# CY8C3246PVI_147 register map
File version: 0.1
CY8C32
Registers are 8-bit, read-write, no defined reset value unless marked. A register's access mark holds for its fields unless they carry their own. Offsets are from the block's base; lines under a group give offsets from that group; [hi:lo] are bit positions; {n}, {i} and the like mark numbered series; 'fields as' and 'values as' point back to an identical list; <NAME> marks a mode.

## Memory map
0x000043A3 PACER_TIMER size 0xB64
0x000043AA ADC size 0x17E0
0x00006404 MY_TIMER size 0x92
0x0000640B COUNTER_ENC size 0x91
0x0000642D UART_RS485 size 0x43 — UART
0x0000646E FF_STATUS size 0x31
0x00006474 FTDI_ENABLE_REG size 0x1
0x0000647C MOTOR_ON_OFF size 0x1
0x0000647D RS485_CTS size 0x1
0x0000647F RESET_FF size 0x1
0x00006527 PWM_MOTORS size 0x71
0x00006574 MOTOR_DIR size 0x1
0x0000657B LED_REG size 0x1

## LED_REG
Base 0x0000657B
0x00 LED_REG_CONTROL_REG

## RS485_CTS
Base 0x0000647D
Registers as LED_REG (with LED_REG read as RS485_CTS).

## RESET_FF
Base 0x0000647F
Registers as LED_REG (with LED_REG read as RESET_FF).

## MOTOR_ON_OFF
Base 0x0000647C
Registers as LED_REG (with LED_REG read as MOTOR_ON_OFF).

## FTDI_ENABLE_REG
Base 0x00006474
Registers as LED_REG (with LED_REG read as FTDI_ENABLE_REG).

## MOTOR_DIR
Base 0x00006574
Registers as LED_REG (with LED_REG read as MOTOR_DIR).

## FF_STATUS
Base 0x0000646E
0x00 FF_STATUS_STATUS_REG
0x20 FF_STATUS_MASK_REG
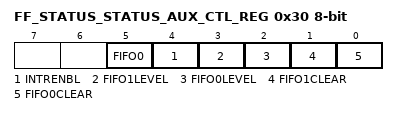
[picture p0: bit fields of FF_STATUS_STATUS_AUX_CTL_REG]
0x30 FF_STATUS_STATUS_AUX_CTL_REG
  [5] FIFO0 — FIFO0 clear
    1=ENABLED (Enable counter); 0=DISABLED (Disable counter)
  [4] INTRENBL — Enables or disables the Interrupt
    1=ENABLED (Interrupt enabled); 0=DISABLED (Interrupt disabled)
  [3] FIFO1LEVEL — FIFO level
    1=ENABLED (FIFO LVL: input mode: FIFO at least 1/2 empty; output mode: FIFO at least 1/2 full); 0=DISABLED (FIFO LVL: input mode: FIFO not full; output mode: FIFO not empty)
  [2] FIFO0LEVEL — FIFO level
    values as FIFO1LEVEL
  [1] FIFO1CLEAR — FIFO clear
    1=ENABLED (Clear FIFO state); 0=DISABLED (Normal FIFO operation)
  [0] FIFO0CLEAR — FIFO clear
    values as FIFO1CLEAR

## MY_TIMER
Base 0x00006404
0x00 MY_TIMER_COUNTER 16-bit — UDB.A0 - Current Down Counter Value
0x20 MY_TIMER_PERIOD 16-bit — UDB.D0 - Assigned Period
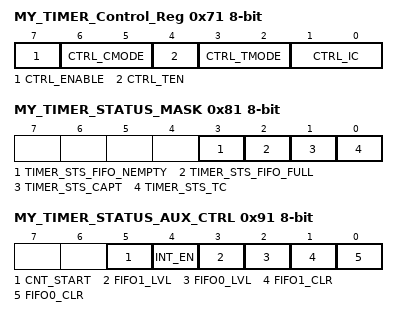
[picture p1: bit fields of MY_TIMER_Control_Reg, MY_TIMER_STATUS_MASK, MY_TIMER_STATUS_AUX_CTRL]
0x71 MY_TIMER_Control_Reg — UDB Control Register - Assigned Control Register Value
  [7] CTRL_ENABLE — Enable the Timer
  [6:5] CTRL_CMODE — Capture Mode
  [4] CTRL_TEN — Trigger Enable Bit
  [3:2] CTRL_TMODE — Trigger Mode
  [1:0] CTRL_IC — Interrupt Count
0x81 MY_TIMER_STATUS_MASK — UDB Status bits Interrupt Mask Enable Register
  [3] TIMER_STS_FIFO_NEMPTY ro — FIFO Empty status
  [2] TIMER_STS_FIFO_FULL ro — FIFO Full Status
  [1] TIMER_STS_CAPT ro — Enables the Interrupt on Capture
  [0] TIMER_STS_TC ro — Enables the Interrupt on TC
0x91 MY_TIMER_STATUS_AUX_CTRL — UDB Auxilliary Control Register
  [5] CNT_START — FIFO0 clear
    0=E_CNT_START0 (Disable counter); 1=E_CNT_START1 (Enable counter)
  [4] INT_EN
    0=E_INT_EN0 (Interrupt disabled); 1=E_INT_EN1 (Interrupt enabled)
  [3] FIFO1_LVL — FIFO level
    0=E_FIFO_LVL_0 (FIFO LVL: input mode: FIFO not full; output mode: FIFO not empty); 1=E_FIFO_LVL_1 (FIFO LVL: input mode: FIFO at least 1/2 empty; output mode: FIFO at least 1/2 full)
  [2] FIFO0_LVL — FIFO level
    values as FIFO1_LVL
  [1] FIFO1_CLR — FIFO1 clear
    0=E_FIFO_CLR_0 (Normal FIFO operation); 1=E_FIFO_CLR_1 (Clear FIFO state)
  [0] FIFO0_CLR — FIFO0 clear
    values as FIFO1_CLR

## UART_RS485 — UART
Base 0x0000642D
0x00 RX_UART_RS485_RX_ADDRESS1 — RX Address1 Register
0x10 RX_UART_RS485_RX_ADDRESS2 — RX Address2 Register
0x20 RX_UART_RS485_RX_DATA — RX Data Register
0x22 TX_UART_RS485_TX_DATA — TX Data Register
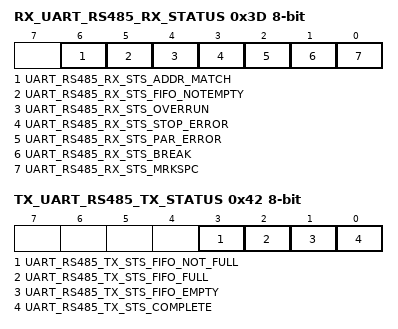
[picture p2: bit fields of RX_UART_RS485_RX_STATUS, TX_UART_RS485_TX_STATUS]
0x3D RX_UART_RS485_RX_STATUS — RX status register
  [6] UART_RS485_RX_STS_ADDR_MATCH ro, [5] UART_RS485_RX_STS_FIFO_NOTEMPTY ro, [4] UART_RS485_RX_STS_OVERRUN ro, [3] UART_RS485_RX_STS_STOP_ERROR ro, [2] UART_RS485_RX_STS_PAR_ERROR ro, [1] UART_RS485_RX_STS_BREAK ro, [0] UART_RS485_RX_STS_MRKSPC ro
0x42 TX_UART_RS485_TX_STATUS — TX status register
  [3] UART_RS485_TX_STS_FIFO_NOT_FULL ro, [2] UART_RS485_TX_STS_FIFO_FULL ro, [1] UART_RS485_TX_STS_FIFO_EMPTY ro, [0] UART_RS485_TX_STS_COMPLETE ro
